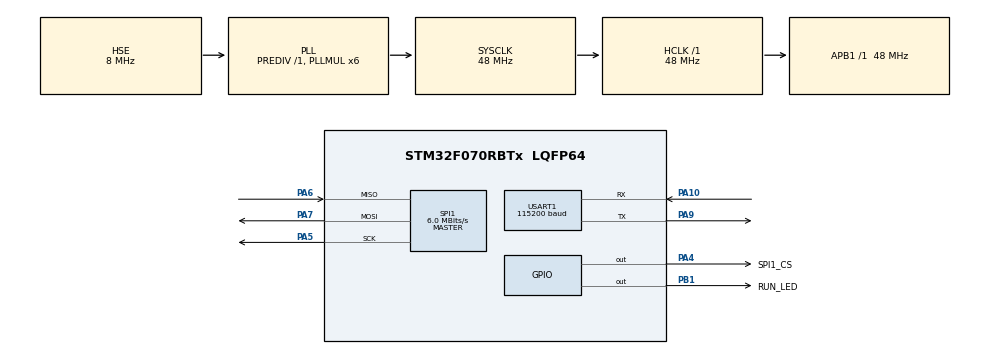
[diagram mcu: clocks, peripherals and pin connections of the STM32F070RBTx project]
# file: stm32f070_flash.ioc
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Mcu.Family=STM32F0
Mcu.Name=STM32F070RBTx
Mcu.Package=LQFP64
PA10.Mode=Asynchronous
PA10.Signal=USART1_RX
PA4.GPIO_Label=SPI1_CS
PA4.GPIO_ModeDefaultOutputPP=GPIO_MODE_OUTPUT_PP
PA4.GPIO_PuPd=GPIO_NOPULL
PA4.GPIO_Speed=GPIO_SPEED_FREQ_LOW
PA4.PinState=GPIO_PIN_RESET
PA4.Signal=GPIO_Output
PA5.Mode=Full_Duplex_Master
PA5.Signal=SPI1_SCK
PA6.Mode=Full_Duplex_Master
PA6.Signal=SPI1_MISO
PA7.Mode=Full_Duplex_Master
PA7.Signal=SPI1_MOSI
PA9.Mode=Asynchronous
PA9.Signal=USART1_TX
PB1.GPIO_Label=RUN_LED
PB1.GPIO_PuPd=GPIO_PULLUP
PB1.GPIO_Speed=GPIO_SPEED_FREQ_HIGH
PB1.PinState=GPIO_PIN_SET
PB1.Signal=GPIO_Output
PC14-OSC32_IN.Mode=LSE-External-Oscillator
PC14-OSC32_IN.Signal=RCC_OSC32_IN
PC15-OSC32_OUT.Mode=LSE-External-Oscillator
PC15-OSC32_OUT.Signal=RCC_OSC32_OUT
PF0-OSC_IN.Mode=HSE-External-Oscillator
PF0-OSC_IN.Signal=RCC_OSC_IN
PF1-OSC_OUT.Mode=HSE-External-Oscillator
PF1-OSC_OUT.Signal=RCC_OSC_OUT
ProjectManager.HeapSize=0x200
ProjectManager.StackSize=0x400
ProjectManager.TargetToolchain=MDK-ARM V5
RCC.AHBFreq_Value=48000000
RCC.APB1Freq_Value=48000000
RCC.APB1TimFreq_Value=48000000
RCC.HCLKFreq_Value=48000000
RCC.PLLMUL=RCC_PLL_MUL6
RCC.PLLSourceVirtual=RCC_PLLSOURCE_HSE
RCC.SYSCLKFreq_VALUE=48000000
RCC.SYSCLKSource=RCC_SYSCLKSOURCE_PLLCLK
SPI1.BaudRatePrescaler=SPI_BAUDRATEPRESCALER_8
SPI1.CalculateBaudRate=6.0 MBits/s
SPI1.DataSize=SPI_DATASIZE_8BIT
SPI1.Direction=SPI_DIRECTION_2LINES
SPI1.Mode=SPI_MODE_MASTER
SPI1.VirtualType=VM_MASTER
USART1.BaudRate=115200
USART1.VirtualMode-Asynchronous=VM_ASYNC
board=custom

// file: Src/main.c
/* USER CODE BEGIN Header */
/**
  ******************************************************************************
  * @file           : main.c
  * @brief          : Main program body
  ******************************************************************************
  * @attention
  *
  * <h2><center>&copy; Copyright (c) 2019 STMicroelectronics.
  * All rights reserved.</center></h2>
  *
  * This software component is licensed by ST under BSD 3-Clause license,
  * the "License"; You may not use this file except in compliance with the
  * License. You may obtain a copy of the License at:
  *                        opensource.org/licenses/BSD-3-Clause
  *
  ******************************************************************************
  */
/* USER CODE END Header */

#include "main.h"
#include "spi.h"
#include "usart.h"
#include "gpio.h"

#include "spi_flash.h"

void SystemClock_Config(void);

/* USER CODE BEGIN 0 */
int fputc(int ch, FILE *f)
{
    uint8_t data = ch;
    HAL_UART_Transmit(&huart1, &data, 1, 0xFFFF);
    return ch;
}
/* USER CODE END 0 */
uint16_t ret = 0x00;
uint16_t flash_id[10] = {0x00};
uint8_t read_buf[512] = {0x00};
uint8_t write_buf[512] = {0x00};
int main(void)
{

    /* MCU Configuration--------------------------------------------------------*/

    /* Reset of all peripherals, Initializes the Flash interface and the Systick. */
    HAL_Init();

    /* Configure the system clock */
    SystemClock_Config();

    /* Initialize all configured peripherals */
    MX_GPIO_Init();
    MX_SPI1_Init();
    MX_USART1_UART_Init();

    for(uint16_t i = 0; i < 500; i++)
    {
        write_buf[i] = i;
    }
    /* Infinite loop */
    /* USER CODE BEGIN WHILE */
    while (1)
    {
        HAL_GPIO_TogglePin(RUN_LED_GPIO_Port, RUN_LED_Pin);

        /* USER CODE END WHILE */
        ret = flash_read_id();

        printf("ret = %x \n", ret);

        ret = flash_sector_erase_4KByte(100);
        printf("erase ret = %d \n", ret);

			  ret = flash_read_data(0x00, read_buf, 500);
        printf("read ret = %d \n", ret);

        for(uint16_t i = 0; i < 500; i++)
        {
            printf("%X ", read_buf[i]);
        }

        spi_flash_write_data(0,write_buf,258);

			//flash_write_page(100,write_buf,256);

        ret = flash_read_data(0x00, read_buf, 500);
        printf("read ret = %d \n", ret);

        for(uint16_t i = 0; i < 500; i++)
        {
            printf("%X ", read_buf[i]);
        }

        printf("\n\n");

        HAL_Delay(1000);
    }
}

void SystemClock_Config(void)
{
    RCC_OscInitTypeDef RCC_OscInitStruct = {0};
    RCC_ClkInitTypeDef RCC_ClkInitStruct = {0};
    RCC_PeriphCLKInitTypeDef PeriphClkInit = {0};

    /** Initializes the CPU, AHB and APB busses clocks
    */
    RCC_OscInitStruct.OscillatorType = RCC_OSCILLATORTYPE_HSE;
    RCC_OscInitStruct.HSEState = RCC_HSE_ON;
    RCC_OscInitStruct.PLL.PLLState = RCC_PLL_ON;
    RCC_OscInitStruct.PLL.PLLSource = RCC_PLLSOURCE_HSE;
    RCC_OscInitStruct.PLL.PLLMUL = RCC_PLL_MUL6;
    RCC_OscInitStruct.PLL.PREDIV = RCC_PREDIV_DIV1;
    if (HAL_RCC_OscConfig(&RCC_OscInitStruct) != HAL_OK)
    {
        Error_Handler();
    }
    /** Initializes the CPU, AHB and APB busses clocks
    */
    RCC_ClkInitStruct.ClockType = RCC_CLOCKTYPE_HCLK | RCC_CLOCKTYPE_SYSCLK
                                  | RCC_CLOCKTYPE_PCLK1;
    RCC_ClkInitStruct.SYSCLKSource = RCC_SYSCLKSOURCE_PLLCLK;
    RCC_ClkInitStruct.AHBCLKDivider = RCC_SYSCLK_DIV1;
    RCC_ClkInitStruct.APB1CLKDivider = RCC_HCLK_DIV1;

    if (HAL_RCC_ClockConfig(&RCC_ClkInitStruct, FLASH_LATENCY_1) != HAL_OK)
    {
        Error_Handler();
    }
    PeriphClkInit.PeriphClockSelection = RCC_PERIPHCLK_USART1;
    PeriphClkInit.Usart1ClockSelection = RCC_USART1CLKSOURCE_PCLK1;
    if (HAL_RCCEx_PeriphCLKConfig(&PeriphClkInit) != HAL_OK)
    {
        Error_Handler();
    }
}

void Error_Handler(void)
{
}

/************************ (C) COPYRIGHT STMicroelectronics *****END OF FILE****/
